# cslr_utopia register map
Vendor: Texas Instruments
Peripheral module from a debugger description file.
Registers are 32-bit, access not given, reset 0x0 unless marked. A register's access mark holds for its fields unless they carry their own. Offsets are as the file gives them; lines under a group give offsets from that group; [hi:lo] are bit positions; {n}, {i} and the like mark numbered series; 'fields as' and 'values as' point back to an identical list; <NAME> marks a mode.

## UTOPIA2 — Utopia is an ATM controller (ATMC) slave device that interfaces to a master ATM controller. The UTOPIA used on Himalaya configured as slave only interface.
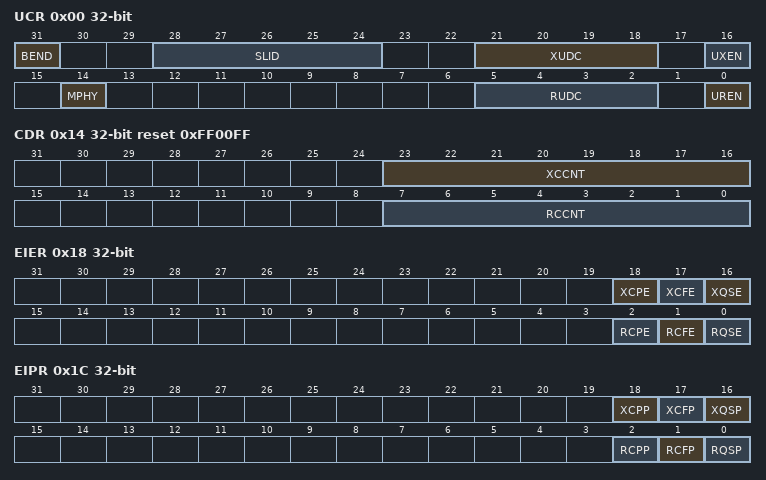
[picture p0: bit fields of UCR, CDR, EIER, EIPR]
0x00 UCR — UTOPIA Control Register
  [31] BEND rw — Big Endian Mode enable bit for data transferred via UTOPIA interface.
    0=LITTLE (Data is assembled to conform to Little-endian format); 1=BIG (Data is assembled to conform to Big-endian format)
  [28:24] SLID rw — Slave ID: Applicable in Slave and MPHY mode.This 5 bit value is used to identify the UTOPIA in a MPHY set up.Does not apply to single-PHY slave operation (MPHY = 0)
  [21:18] XUDC rw — Transmit User Defined Cell
  [16] UXEN rw — UTOPIA Transmitter Enable
    0=TX_PORT_DISABLE (UTOPIA port Transmitter Disabled and in reset state.); 1=TX_PORT_ENABLE (UTOPIA port Transmitter Enabled.)
  [14] MPHY rw — UTOPIA Receive/Transmit Multi-PHY Mode. MPHY mode is by default.
    0=SINGLE_PHYMODE (Single PHY mode selected.); 1=MULTI_PHYMODE (Multi-PHY mode selected.)
  [5:2] RUDC rw — Receive User Defined Cell
  [0] UREN rw — UTOPIA Receiver Enable
    0=RX_PORT_DISABLE (UTOPIA port receiver is disabled and in reset state); 1=RX_PORT_ENABLE (UTOPIA port receiver is enabled)
0x14 CDR reset 0xFF00FF — Clock Detect Register
  [23:16] XCCNT rw — Transmit clock count bits specify the number of peripheral clock cycles that the external UTOPIA transmit clock (UXCLK) must have a low-to-high transition to avoid a reset of the transmit interface.
    0=DISABLE (Transmit Clock Detection Disabled.)
  [7:0] RCCNT rw — Receive clock count bits specify the number of peripheral clock cycles that the external UTOPIA receive clock must have a low-to-high transition to avoid a reset of the receive interface.
    0=DISABLE (Receive Clock Detection disabled)
0x18 EIER — Error Interrupt Enable Register
  [18] XCPE rw — Transmit Clock Present Interrupt Enable
    0=DISABLE (Transmit Clock Present Interrupt Disabled); 1=ENABLE (Transmit Clock Present Interrupt Enabled)
  [17] XCFE rw — Transmit Clock Failed Interrupt Enable
    0=DISABLE (Transmit Clock Failed Interrupt Disabled); 1=ENABLE (Transmit Clock Failed Interrupt Enabled)
  [16] XQSE rw — Transmit Queue Stall Interrupt Enable
    0=DISABLE (Transmit Queue Stall Interrupt Disabled); 1=ENABLE (Transmit Queue Stall Interrupt Enabled)
  [2] RCPE rw — Receive Clock Present Interrupt Enable
    0=DISABLE (Receive Clock Present Interrupt Disabled); 1=ENABLE (Receive Clock Present Interrupt Enabled)
  [1] RCFE rw — Receive Clock Failed Interrupt Enable
    0=DISABLE (Receive Clock Failed Interrupt Disabled); 1=ENABLE (Receive Clock Failed Interrupt Enabled)
  [0] RQSE rw — Receive Queue Stall Interrupt Enable
    0=DISABLE (Receive Queue Stall Interrupt Disabled); 1=ENABLE (Receive Queue Stall Interrupt Enabled)
0x1C EIPR — Error Interrupt Pending Register
  [18] XCPP — Transmit Clock Present Interrupt Pending.XCPP is valid regardless of UXEN is set or not. (access RC)
  [17] XCFP — Transmit Clock Failed Interrupt Pending.Activated only when UXEN=1. (access RC)
  [16] XQSP ro — Transmit Queue Stall Interrupt Pending.Stalled untill the queue is drained and space is available.
  [2] RCPP — Receive Clock Present Interrupt Pending.RCPP is valid regardless if UREN is set or not. (access RC)
  [1] RCFP — Receive Clock Failed Interrupt Pending.Activated only when UTOPIA Receive Interface(UREN=1) (access RC)
  [0] RQSP ro — Receive Queue Stall Interrupt Pending
